# LargeDummyDevice register map
File version: 1.0
Registers are 32-bit, read-write, no defined reset value unless marked. A register's access mark holds for its fields unless they carry their own. Offsets are from the block's base; [hi:lo] are bit positions.

## PERIPHERAL_10
Base 0x40009000
0x04 REG_1 — Register 1
  [31:29] FIELD_1, [21:19] FIELD_2, [18:17] FIELD_3, [19:16] FIELD_6, [11] FIELD_5, [7:5] FIELD_4
0x08 REG_2 — Register 2
  [34:31] FIELD_15, [33:29] FIELD_10, [28] FIELD_4, [29:25] FIELD_2, [23:22] FIELD_7, [25:21] FIELD_3, [24:21] FIELD_19, [20:19] FIELD_14, [20:17] FIELD_1, [20:16] FIELD_9, [19:16] FIELD_17, [14:12] FIELD_13, [15:12] FIELD_18, [13:11] FIELD_11, [10:9] FIELD_16, [10:7] FIELD_6, [7:6] FIELD_8, [4] FIELD_12, [4:0] FIELD_5
0x0C REG_3 — Register 3
  [33:31] FIELD_8, [35:31] FIELD_14, [30] FIELD_22, [29] FIELD_3, [31:29] FIELD_26, [31:27] FIELD_5, [27:26] FIELD_29, [28:25] FIELD_7, [27:25] FIELD_18, [24:23] FIELD_27, [25:21] FIELD_19, [20] FIELD_16, [19:18] FIELD_1, [21:17] FIELD_6, [18:17] FIELD_17, [16] FIELD_10, [20:16] FIELD_20, [16:15] FIELD_13, [19:15] FIELD_15, [18:14] FIELD_2, [16:14] FIELD_9, [17:14] FIELD_24, [13] FIELD_12, [17:13] FIELD_25, [12:10] FIELD_11, [13:9] FIELD_28, [4] FIELD_21, [4:1] FIELD_23, [0] FIELD_4
0x10 REG_4 — Register 4
  [35:31] FIELD_5, [33:31] FIELD_21, [29] FIELD_14, [26:25] FIELD_7, [26:24] FIELD_22, [23] FIELD_1, [23:22] FIELD_24, [24:21] FIELD_9, [21] FIELD_13, [25:21] FIELD_19, [23:20] FIELD_23, [21:20] FIELD_26, [20:19] FIELD_3, [19] FIELD_15, [20:19] FIELD_18, [16] FIELD_17, [15] FIELD_2, [16:15] FIELD_8, [19:15] FIELD_12, [16:12] FIELD_20, [13:11] FIELD_6, [15:11] FIELD_10, [13:9] FIELD_25, [7] FIELD_4, [5] FIELD_16, [3] FIELD_11
0x14 REG_5 — Register 5
  [31] FIELD_23, [32:31] FIELD_28, [34:31] FIELD_30, [33:30] FIELD_29, [29:28] FIELD_13, [31:27] FIELD_4, [30:26] FIELD_7, [28:26] FIELD_12, [27:25] FIELD_9, [26:25] FIELD_16, [29:25] FIELD_19, [25:22] FIELD_5, [23:22] FIELD_22, [23:21] FIELD_15, [21] FIELD_20, [18] FIELD_31, [21:17] FIELD_17, [20:16] FIELD_3, [16] FIELD_18, [16] FIELD_25, [19:15] FIELD_6, [14:13] FIELD_32, [13:11] FIELD_21, [10] FIELD_1, [14:10] FIELD_8, [13:9] FIELD_26, [12:8] FIELD_14, [11:8] FIELD_24, [7:5] FIELD_11, [5:4] FIELD_27, [5:1] FIELD_2, [2:1] FIELD_10
0x18 REG_6 — Register 6
  [31] FIELD_1, [31:28] FIELD_6, [25:24] FIELD_4, [24:21] FIELD_7, [24:20] FIELD_2, [13:11] FIELD_5, [7] FIELD_3, [7:4] FIELD_9, [3] FIELD_8
0x1C REG_7 — Register 7
  [33:31] FIELD_13, [33:31] FIELD_15, [32:30] FIELD_6, [27:25] FIELD_10, [25] FIELD_14, [23] FIELD_9, [22:19] FIELD_8, [19] FIELD_17, [17:15] FIELD_3, [16:14] FIELD_2, [16:12] FIELD_4, [15:12] FIELD_5, [12:11] FIELD_7, [12:10] FIELD_16, [12:9] FIELD_11, [9:6] FIELD_12, [6:5] FIELD_1, [4] FIELD_18
0x20 REG_8 — Register 8
  [29:28] FIELD_5, [30:28] FIELD_9, [27:23] FIELD_2, [27:23] FIELD_7, [26:22] FIELD_1, [16] FIELD_4, [15:11] FIELD_3, [6] FIELD_6, [4:2] FIELD_8
0x24 REG_9 — Register 9
  [31] FIELD_2, [32:29] FIELD_16, [28:26] FIELD_6, [29:26] FIELD_25, [25] FIELD_13, [23:22] FIELD_5, [23:21] FIELD_11, [23:21] FIELD_15, [22:20] FIELD_24, [21:18] FIELD_12, [21:18] FIELD_20, [17] FIELD_23, [19:16] FIELD_8, [17:16] FIELD_18, [15] FIELD_4, [14] FIELD_19, [17:13] FIELD_3, [15:12] FIELD_7, [15:11] FIELD_22, [11:10] FIELD_9, [13:10] FIELD_14, [10:9] FIELD_21, [6] FIELD_10, [8:6] FIELD_17, [5:4] FIELD_26, [4:1] FIELD_1
0x28 REG_10 — Register 10
  [29:28] FIELD_7, [28:25] FIELD_8, [15] FIELD_1, [17:13] FIELD_5, [11] FIELD_4, [6:3] FIELD_6, [6:2] FIELD_3, [3:1] FIELD_2
0x2C REG_11 — Register 11
  [28:25] FIELD_5, [10:8] FIELD_4, [6:5] FIELD_1, [3:2] FIELD_3, [2:0] FIELD_2
0x30 REG_12 — Register 12
  [31] FIELD_9, [31:29] FIELD_3, [32:28] FIELD_14, [27:25] FIELD_6, [21] FIELD_10, [19] FIELD_1, [18] FIELD_7, [21:17] FIELD_2, [20:16] FIELD_15, [16:14] FIELD_12, [12:10] FIELD_8, [13:9] FIELD_11, [9] FIELD_16, [2] FIELD_13, [2:0] FIELD_4, [1:0] FIELD_5
0x34 REG_13 — Register 13
  [27:25] FIELD_21, [24:20] FIELD_5, [24:20] FIELD_17, [20:17] FIELD_3, [19:17] FIELD_15, [19:16] FIELD_12, [18:15] FIELD_7, [17:13] FIELD_9, [14:12] FIELD_10, [13:10] FIELD_1, [9:8] FIELD_4, [8:7] FIELD_2, [6:5] FIELD_18, [7:5] FIELD_20, [5:4] FIELD_6, [4] FIELD_8, [5:4] FIELD_13, [6:4] FIELD_19, [4:2] FIELD_11, [4:1] FIELD_16, [3:0] FIELD_14
0x38 REG_14 — Register 14
  [31] FIELD_12, [34:31] FIELD_17, [30:26] FIELD_16, [28:25] FIELD_20, [25] FIELD_24, [24] FIELD_5, [27:23] FIELD_4, [25:22] FIELD_9, [19] FIELD_18, [19:16] FIELD_3, [17:14] FIELD_8, [15:13] FIELD_1, [14:13] FIELD_11, [13:12] FIELD_22, [12:11] FIELD_15, [11] FIELD_23, [10:8] FIELD_25, [8:6] FIELD_2, [10:6] FIELD_21, [8:4] FIELD_6, [6:4] FIELD_13, [3] FIELD_7, [6:3] FIELD_10, [6:3] FIELD_19, [4:1] FIELD_14, [3:1] FIELD_26
0x3C REG_15 — Register 15
  [33:31] FIELD_16, [32:31] FIELD_19, [32:31] FIELD_22, [32:29] FIELD_5, [33:29] FIELD_8, [26:24] FIELD_2, [27:23] FIELD_13, [25:23] FIELD_18, [23:22] FIELD_3, [23:22] FIELD_15, [19:16] FIELD_7, [16] FIELD_12, [16:15] FIELD_4, [19:15] FIELD_25, [16:13] FIELD_11, [13:10] FIELD_20, [11:8] FIELD_9, [10:8] FIELD_14, [11:7] FIELD_1, [9:7] FIELD_21, [8:5] FIELD_6, [6:2] FIELD_17, [5:1] FIELD_23, [0] FIELD_10, [0] FIELD_24
0x40 REG_16 — Register 16
  [35:31] FIELD_12, [34:31] FIELD_13, [29] FIELD_17, [28] FIELD_5, [29:27] FIELD_2, [29:26] FIELD_19, [26:25] FIELD_10, [23:22] FIELD_8, [21:20] FIELD_9, [24:20] FIELD_20, [22:20] FIELD_22, [19:17] FIELD_1, [21:17] FIELD_21, [19:15] FIELD_23, [15:13] FIELD_18, [13:12] FIELD_15, [13:10] FIELD_6, [10:9] FIELD_16, [8:6] FIELD_7, [6:3] FIELD_11, [2] FIELD_3, [4:2] FIELD_4, [2:1] FIELD_14
0x44 REG_17 — Register 17
  [25:23] FIELD_7, [22] FIELD_10, [23:21] FIELD_6, [20:18] FIELD_5, [18:15] FIELD_2, [8:7] FIELD_1, [10:7] FIELD_3, [8:6] FIELD_8, [6:2] FIELD_9, [1] FIELD_4
0x48 REG_18 — Register 18
  [19:18] FIELD_1, [19:17] FIELD_6, [19:16] FIELD_9, [18:14] FIELD_5, [12:11] FIELD_8, [13:10] FIELD_7, [13:9] FIELD_4, [7:3] FIELD_2, [2] FIELD_3
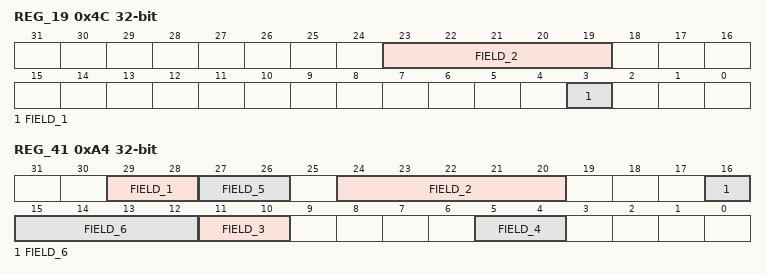
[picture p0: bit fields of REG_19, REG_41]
0x4C REG_19 — Register 19
  [23:19] FIELD_2, [3] FIELD_1
0x50 REG_20 — Register 20
  [35:31] FIELD_13, [32:30] FIELD_16, [30:28] FIELD_12, [27:25] FIELD_7, [24:23] FIELD_14, [23] FIELD_17, [24:22] FIELD_2, [22:21] FIELD_10, [22:19] FIELD_21, [15:14] FIELD_15, [16:14] FIELD_19, [16:13] FIELD_5, [12] FIELD_6, [15:11] FIELD_20, [13:10] FIELD_9, [9] FIELD_3, [8] FIELD_22, [10:6] FIELD_8, [6:5] FIELD_1, [8:4] FIELD_11, [6:3] FIELD_18, [1] FIELD_4
0x54 REG_21 — Register 21
  [34:31] FIELD_8, [29:28] FIELD_5, [29:28] FIELD_15, [31:27] FIELD_4, [25] FIELD_3, [15] FIELD_12, [17:15] FIELD_19, [10] FIELD_6, [13:10] FIELD_9, [9] FIELD_10, [10:8] FIELD_1, [11:7] FIELD_17, [6:4] FIELD_2, [8:4] FIELD_7, [8:4] FIELD_13, [4] FIELD_16, [4:1] FIELD_18, [4:0] FIELD_11, [2:0] FIELD_14
0x58 REG_22 — Register 22
  [12:8] FIELD_1
0x5C REG_23 — Register 23
  [31:29] FIELD_16, [30:28] FIELD_1, [32:28] FIELD_8, [24] FIELD_9, [27:23] FIELD_14, [25:21] FIELD_10, [21:20] FIELD_17, [22:19] FIELD_7, [21:18] FIELD_3, [18] FIELD_11, [19:15] FIELD_12, [15] FIELD_15, [17:14] FIELD_6, [16:14] FIELD_13, [14:13] FIELD_20, [13:11] FIELD_4, [15:11] FIELD_5, [8:5] FIELD_18, [5:4] FIELD_19, [2] FIELD_2
0x60 REG_24 — Register 24
  [32:31] FIELD_23, [34:30] FIELD_6, [30:29] FIELD_4, [31:29] FIELD_16, [28:26] FIELD_10, [26:24] FIELD_2, [27:24] FIELD_11, [27:24] FIELD_26, [23:22] FIELD_15, [23:22] FIELD_19, [25:21] FIELD_7, [22:21] FIELD_22, [24:20] FIELD_28, [19:18] FIELD_1, [20:17] FIELD_18, [18:15] FIELD_13, [15:14] FIELD_14, [14] FIELD_25, [12] FIELD_8, [14:12] FIELD_12, [12:11] FIELD_3, [11:8] FIELD_5, [10:7] FIELD_9, [8:7] FIELD_17, [4] FIELD_21, [4] FIELD_24, [6:3] FIELD_20, [5:1] FIELD_27
0x64 REG_25 — Register 25
  [31] FIELD_17, [31:28] FIELD_6, [29:28] FIELD_7, [30:26] FIELD_4, [29:25] FIELD_18, [24:23] FIELD_19, [20] FIELD_13, [18] FIELD_15, [16:15] FIELD_5, [16:15] FIELD_11, [16:13] FIELD_9, [17:13] FIELD_20, [13:11] FIELD_10, [14:10] FIELD_8, [8] FIELD_16, [9:7] FIELD_12, [8:5] FIELD_2, [7:3] FIELD_3, [3] FIELD_14, [3:0] FIELD_1
0x68 REG_26 — Register 26
  [32:30] FIELD_14, [32:29] FIELD_3, [29:28] FIELD_23, [31:27] FIELD_17, [27] FIELD_19, [27] FIELD_22, [30:26] FIELD_4, [26] FIELD_12, [29:26] FIELD_15, [26:24] FIELD_8, [23] FIELD_1, [24:23] FIELD_11, [23] FIELD_25, [26:22] FIELD_7, [26:22] FIELD_18, [24:20] FIELD_16, [22:18] FIELD_9, [16] FIELD_2, [15] FIELD_26, [11:8] FIELD_21, [11:8] FIELD_24, [11:7] FIELD_10, [9:7] FIELD_20, [9:6] FIELD_6, [9:6] FIELD_13, [5:2] FIELD_5
0x6C REG_27 — Register 27
  [32:29] FIELD_8, [30:28] FIELD_3, [26:25] FIELD_7, [25:21] FIELD_9, [20] FIELD_5, [14:12] FIELD_2, [11] FIELD_10, [7:5] FIELD_4, [4] FIELD_1, [3] FIELD_6
0x70 REG_28 — Register 28
  [35:31] FIELD_5, [28:27] FIELD_8, [27:24] FIELD_3, [27:23] FIELD_4, [24:20] FIELD_11, [19] FIELD_7, [14:12] FIELD_6, [10:8] FIELD_1, [10:6] FIELD_10, [6:5] FIELD_2, [4:2] FIELD_9
0x74 REG_29 — Register 29
  [31:28] FIELD_8, [27] FIELD_14, [30:26] FIELD_3, [26] FIELD_16, [26:25] FIELD_13, [28:25] FIELD_18, [25:24] FIELD_5, [21] FIELD_6, [18] FIELD_9, [17] FIELD_20, [17:16] FIELD_21, [16:13] FIELD_19, [15:11] FIELD_1, [12:8] FIELD_2, [6] FIELD_7, [9:6] FIELD_10, [6:4] FIELD_4, [3] FIELD_12, [5:2] FIELD_17, [4:0] FIELD_11, [3:0] FIELD_15
0x78 REG_30 — Register 30
  [28] FIELD_4, [31:27] FIELD_3, [27] FIELD_6, [29:25] FIELD_11, [25:21] FIELD_15, [20] FIELD_10, [16:14] FIELD_13, [14:13] FIELD_2, [14:12] FIELD_12, [10] FIELD_7, [10] FIELD_9, [9] FIELD_1, [7:3] FIELD_5, [2] FIELD_8, [4:0] FIELD_14, [0] FIELD_16
0x7C REG_31 — Register 31
  [29] FIELD_1, [25:24] FIELD_3, [18:14] FIELD_5, [16:14] FIELD_6, [15:13] FIELD_7, [2] FIELD_4, [4:0] FIELD_2
0x80 REG_32 — Register 32
  [20:16] FIELD_3, [17:15] FIELD_1, [4] FIELD_2
0x84 REG_33 — Register 33
  [27:25] FIELD_1, [28:25] FIELD_5, [22:18] FIELD_10, [18:16] FIELD_8, [18:15] FIELD_7, [13:10] FIELD_2, [14:10] FIELD_4, [10] FIELD_6, [10:6] FIELD_3, [4:2] FIELD_9
0x88 REG_34 — Register 34
  [29:28] FIELD_1, [30:28] FIELD_12, [27:26] FIELD_7, [24:20] FIELD_15, [19] FIELD_11, [18:17] FIELD_14, [18:15] FIELD_2, [17:15] FIELD_3, [19:15] FIELD_5, [17:14] FIELD_8, [15:13] FIELD_9, [13:10] FIELD_16, [10:9] FIELD_10, [12:8] FIELD_17, [10:6] FIELD_6, [7:4] FIELD_13, [3:1] FIELD_4
0x8C REG_35 — Register 35
  [33:31] FIELD_14, [33:30] FIELD_12, [31:29] FIELD_3, [31:28] FIELD_18, [30:27] FIELD_16, [27:25] FIELD_17, [24] FIELD_4, [23] FIELD_1, [23] FIELD_8, [19:17] FIELD_5, [17:15] FIELD_2, [12:11] FIELD_6, [13:11] FIELD_11, [9:8] FIELD_7, [6] FIELD_15, [5:4] FIELD_9, [3] FIELD_10, [3:2] FIELD_13
0x90 REG_36 — Register 36
  [32:31] FIELD_4, [32:31] FIELD_13, [30:27] FIELD_2, [19:15] FIELD_16, [18:14] FIELD_14, [16:13] FIELD_6, [15:13] FIELD_9, [13:11] FIELD_5, [11:8] FIELD_12, [6:5] FIELD_8, [5] FIELD_10, [8:4] FIELD_11, [4] FIELD_18, [4:1] FIELD_1, [4:1] FIELD_3, [2:1] FIELD_17, [2:0] FIELD_7, [0] FIELD_15
0x94 REG_37 — Register 37
  [29:28] FIELD_3, [30:28] FIELD_25, [26] FIELD_26, [29:25] FIELD_6, [25:24] FIELD_4, [25:24] FIELD_21, [27:23] FIELD_29, [23:22] FIELD_27, [24:20] FIELD_5, [24:20] FIELD_22, [20] FIELD_30, [21:17] FIELD_2, [18:17] FIELD_24, [19:16] FIELD_8, [17:15] FIELD_12, [18:14] FIELD_10, [17:13] FIELD_15, [14:13] FIELD_17, [11] FIELD_9, [11:10] FIELD_14, [10] FIELD_19, [11:10] FIELD_20, [10] FIELD_23, [10] FIELD_28, [11:7] FIELD_7, [7:6] FIELD_13, [9:5] FIELD_1, [5:3] FIELD_11, [0] FIELD_16, [1:0] FIELD_18
0x98 REG_38 — Register 38
  [33:29] FIELD_13, [33:29] FIELD_17, [32:29] FIELD_18, [31:27] FIELD_12, [28:25] FIELD_5, [27:23] FIELD_15, [23:22] FIELD_23, [21:20] FIELD_22, [15] FIELD_9, [15] FIELD_11, [14:12] FIELD_4, [11] FIELD_2, [13:11] FIELD_3, [13:11] FIELD_6, [11:9] FIELD_10, [10:9] FIELD_21, [9:7] FIELD_19, [6:5] FIELD_1, [7:4] FIELD_7, [4] FIELD_16, [3] FIELD_8, [2:0] FIELD_14, [0] FIELD_20
0x9C REG_39 — Register 39
  [34:31] FIELD_3, [29:28] FIELD_9, [31:27] FIELD_1, [28:25] FIELD_11, [23] FIELD_21, [22:19] FIELD_15, [19:15] FIELD_12, [16:14] FIELD_4, [17:14] FIELD_6, [14] FIELD_17, [18:14] FIELD_22, [15:12] FIELD_8, [15:11] FIELD_2, [12:10] FIELD_5, [13:10] FIELD_20, [8] FIELD_14, [8] FIELD_19, [7:5] FIELD_7, [7:5] FIELD_10, [7:3] FIELD_16, [5:1] FIELD_13, [3:0] FIELD_18, [2:0] FIELD_23
0xA0 REG_40 — Register 40
  [34:30] FIELD_5, [30:27] FIELD_6, [20:19] FIELD_4, [22:19] FIELD_7, [18] FIELD_1, [20:18] FIELD_8, [1:0] FIELD_2, [2:0] FIELD_3
0xA4 REG_41 — Register 41
  [29:28] FIELD_1, [27:26] FIELD_5, [24:20] FIELD_2, [16:12] FIELD_6, [11:10] FIELD_3, [5:4] FIELD_4
0xA8 REG_42 — Register 42
  [28:27] FIELD_14, [27:26] FIELD_7, [25] FIELD_1, [27:23] FIELD_3, [24:22] FIELD_8, [23:20] FIELD_4, [20:18] FIELD_5, [20:18] FIELD_9, [16:14] FIELD_13, [15:11] FIELD_12, [13:9] FIELD_11, [8:7] FIELD_2, [7:6] FIELD_6, [6:5] FIELD_10, [4] FIELD_15
0xAC REG_43 — Register 43
  [24] FIELD_3, [27:23] FIELD_1, [18] FIELD_2, [18:17] FIELD_4, [5] FIELD_5
0xB0 REG_44 — Register 44
  [30] FIELD_6, [32:30] FIELD_12, [31:29] FIELD_10, [30:27] FIELD_21, [31:27] FIELD_26, [30:27] FIELD_27, [28:25] FIELD_9, [26:25] FIELD_22, [26:22] FIELD_16, [23:21] FIELD_11, [23:19] FIELD_5, [19:17] FIELD_18, [19:17] FIELD_19, [20:17] FIELD_23, [17:16] FIELD_3, [20:16] FIELD_14, [18:15] FIELD_20, [15:14] FIELD_1, [17:14] FIELD_2, [15:14] FIELD_7, [15:13] FIELD_4, [13:11] FIELD_15, [9:7] FIELD_13, [8:7] FIELD_24, [6] FIELD_17, [8:5] FIELD_25, [6:4] FIELD_8
0xB4 REG_45 — Register 45
  [31:29] FIELD_5, [26:22] FIELD_1, [25:22] FIELD_10, [21] FIELD_12, [22:20] FIELD_3, [22:20] FIELD_7, [19:16] FIELD_13, [14] FIELD_11, [18:14] FIELD_15, [15:12] FIELD_16, [12:9] FIELD_2, [9] FIELD_4, [8:7] FIELD_14, [7:6] FIELD_6, [8:5] FIELD_17, [7:4] FIELD_8, [2:1] FIELD_18, [4:0] FIELD_9
0xB8 REG_46 — Register 46
  [33:31] FIELD_1, [34:31] FIELD_14, [28] FIELD_5, [26] FIELD_9, [26:24] FIELD_7, [25:23] FIELD_10, [21:19] FIELD_13, [16:14] FIELD_2, [14] FIELD_6, [13:11] FIELD_11, [13:9] FIELD_12, [5] FIELD_3, [6:4] FIELD_8, [4:3] FIELD_15, [6:2] FIELD_4
0xBC REG_47 — Register 47
  [32:31] FIELD_19, [32:28] FIELD_2, [28] FIELD_16, [26:25] FIELD_7, [27:24] FIELD_8, [26:23] FIELD_10, [23] FIELD_11, [27:23] FIELD_22, [21] FIELD_25, [22:20] FIELD_4, [22:20] FIELD_12, [18] FIELD_9, [21:18] FIELD_21, [21:18] FIELD_29, [19:17] FIELD_27, [17:16] FIELD_14, [19:15] FIELD_6, [13:11] FIELD_3, [15:11] FIELD_17, [11:9] FIELD_15, [10:8] FIELD_26, [10:7] FIELD_1, [9:6] FIELD_5, [7:5] FIELD_28, [4:3] FIELD_18, [2] FIELD_24, [4:1] FIELD_13, [1] FIELD_20, [3:0] FIELD_23
0xC0 REG_48 — Register 48
  [29] FIELD_9, [28:27] FIELD_7, [23] FIELD_11, [24:21] FIELD_14, [23:21] FIELD_15, [19:18] FIELD_2, [15:13] FIELD_13, [15:11] FIELD_4, [12:10] FIELD_8, [12:10] FIELD_12, [5] FIELD_1, [7:5] FIELD_6, [5:2] FIELD_3, [4:0] FIELD_5, [3:0] FIELD_10
0xC4 REG_49 — Register 49
  [32:31] FIELD_1, [30] FIELD_6, [28] FIELD_14, [30:28] FIELD_15, [27] FIELD_10, [28:26] FIELD_9, [24] FIELD_5, [26:23] FIELD_3, [26:23] FIELD_8, [22:21] FIELD_11, [23:19] FIELD_7, [15:13] FIELD_13, [11] FIELD_2, [14:11] FIELD_18, [14:10] FIELD_4, [8:6] FIELD_12, [1:0] FIELD_16, [4:0] FIELD_17
